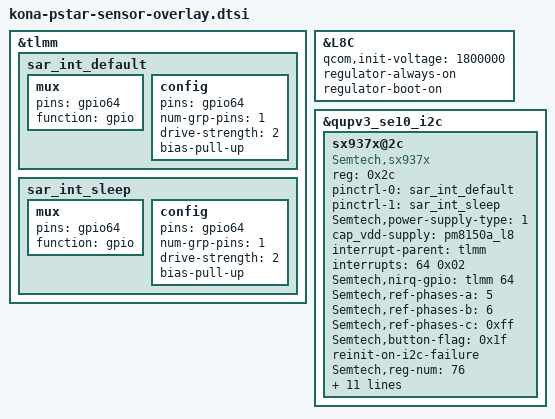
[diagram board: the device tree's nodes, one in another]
/* Copyright (c) 2019, The Linux Foundation. All rights reserved.
 *
 * This program is free software; you can redistribute it and/or modify
 * it under the terms of the GNU General Public License version 2 and
 * only version 2 as published by the Free Software Foundation.
 *
 * This program is distributed in the hope that it will be useful,
 * but WITHOUT ANY WARRANTY; without even the implied warranty of
 * MERCHANTABILITY or FITNESS FOR A PARTICULAR PURPOSE.  See the
 * GNU General Public License for more details.
 */

&tlmm {
	sar_int_default: sar_int_default {
			mux {
				pins = "gpio64";
				function =  "gpio";
			};
			config {
				pins = "gpio64";
				num-grp-pins = <1>;
				drive-strength = <2>;
				bias-pull-up;
			};
	};

	sar_int_sleep: sar_int_sleep {
			mux {
				pins = "gpio64";
				function =  "gpio";
			};
			config {
				pins = "gpio64";
				num-grp-pins = <1>;
				drive-strength = <2>;
				bias-pull-up;
			};
	};
};

&L8C {
	qcom,init-voltage = <1800000>;
	regulator-always-on;
	regulator-boot-on;
	status = "ok";
};

&qupv3_se10_i2c {
	status = "ok";
	sx937x@2c { /* SAR sensor */
		compatible = "Semtech,sx937x";
		reg = <0x2c>;
		pinctrl-names = "default","sleep";
		pinctrl-0 = <&sar_int_default>;
		pinctrl-1 = <&sar_int_sleep>;
		Semtech,power-supply-type = <1>;
		cap_vdd-supply = <&pm8150a_l8>;
		interrupt-parent = <&tlmm>;
		interrupts = <64 0x02>;
		interrupt-names = "sx937x_irq";
		Semtech,nirq-gpio= <&tlmm 64 0x02>;
		/*use PH4/5/6 as the reference sensor
		set it to 0xff if the ref-phases-x is not used*/
		Semtech,ref-phases-a = <5>;
		Semtech,ref-phases-b = <6>;
		Semtech,ref-phases-c = <0xff>;
		Semtech,button-flag = <0x1f>;
		reinit-on-i2c-failure;
		Semtech,reg-num = <76>;
		Semtech,reg-init = <
			0x8024  0x7F00 		/*PHEN, Disable all Phases*/
			0x4004  0x74 		/*irq mask*/
			0x4008  0x8
			0x8008  0x7F000081
			0x4280  0x0
			0x8020  0x32
			0x8028  0xE76 		/*AFE_PARAM_PH0*/
			0x8034  0xA76 		/*AFE_PARAM_PH1*/
			0x8040  0xE76 		/*AFE_PARAM_PH2*/
			0x804C  0x876    	/*AFE_PARAM_PH3*/
			0x8058  0xE76 		/*AFE_PARAM_PH4*/
			0x8064  0x876 		/*AFE_PARAM_PH5*/
			0x8070  0x876 		/*AFE_PARAM_PH6*/
			0x807C  0x876  		/*AFE_PARAM_PH7*/
			/*set CS3 to hiz, because it used as IRQ pin*/
			0x8030  0xBFF9FF 	/*REG_AFEPH_PH0, CS7, ANT1, Bottom center*/
			0x803C  0xFFD9FF 	/*REG_AFEPH_PH1, CS4, ANT2, Top Left*/
			0x8048  0xFFF9EF 	/*REG_AFEPH_PH2, CS5, ANT8, Bottom Right*/
			0x8054  0xFFF9FD	/*REG_AFEPH_PH3, CS1, ANT4, Right*/
			0x8060  0xFEF9FF 	/*REG_AFEPH_PH4, CS0, ANT5, Back center*/
			0x806C  0xF7F9FF 	/*REG_AFEPH_PH5, CS6, ANT1/8_REF, Bottom_Ref*/
			0x8078  0xFFF97F 	/*REG_AFEPH_PH6, CS2, ANT4/5_REF, Middle*/
			0x8084  0xFFF9FF 	/*REG_AFEPH_PH7, NOT USE*/
			0x802C  0x0
			0x8038  0xF3C3CF
			0x8044  0x940250
			0x8050  0x9BC26F
			0x805C  0x990264
			0x8068  0xD4C353
			0x8074  0xB4C2D3
			0x8080  0x0
			0x8098  0x8535
			0x80B8  0x9833
			0x80D8  0x4949
			0x80F8  0x4747
			0x8118  0x6262
			0x8138  0x7628
			0x8158  0x7628
			0x8178  0x0
			0x80A0  0x13130001
			0x80C0  0x17170002
			0x80E0  0x11110002
			0x8100  0x13130002
			0x8120  0x1A1A0002
			0x8140  0x0
			0x8160  0x0
			0x8180  0x0
			0x8188  0x8000015
			0x818C  0x8000016
			0x8190  0x0
			0x8194  0x0
			0x8090  0x46D89000
			0x80B0  0x46D59000
			0x80D0  0x3CDE9000
			0x80F0  0x64C29000
			0x8110  0x3CDE9000
			0x8130  0x2AD67000
			0x8150  0x2AD67000
			0x8170  0x0
			0x8088  0x300002
			0x80A8  0x300002
			0x80C8  0x300002
			0x80E8  0x300002
			0x8108  0x300002
			0x8128  0x500000
			0x8148  0x500000
			0x8168  0x0
			0x808C  0xE060000C
			0x80AC  0xE060000C
			0x80CC  0xE060000C
			0x80EC  0xE060000C
			0x810C  0xE060000C
			0x812C  0xE060000C
			0x814C  0xE060000C
			0x816C  0x0
			0x8024  0x7F7F
			0x4280  0xF
		>;
		/* multi parameters for the different panels,
		"support-panel-names" is the key name of the panel name from the cmdline
		the nums of "Semtech,reg-*" should be same as "Semtech,reg-init" */
		support-panel-num = <2>;
		support-panel-names = "mot_csot_nt37701_667_1080x2400_dsc_cmd","mot_visionox_nt37701_667_1080x2400_dsc_cmd";
		reg-groups-names = "Semtech,reg-0","Semtech,reg-1";
		Semtech,reg-0 = <
			0x8024  0x7F00 		/*PHEN, Disable all Phases*/
			0x4004  0x74 		/*irq mask*/
			0x4008  0x8
			0x8008  0x7F000081
			0x4280  0x0
			0x8020  0x32
			0x8028  0xE76 		/*AFE_PARAM_PH0*/
			0x8034  0xA76 		/*AFE_PARAM_PH1*/
			0x8040  0xE76 		/*AFE_PARAM_PH2*/
			0x804C  0x876    	/*AFE_PARAM_PH3*/
			0x8058  0xE76 		/*AFE_PARAM_PH4*/
			0x8064  0x876 		/*AFE_PARAM_PH5*/
			0x8070  0x876 		/*AFE_PARAM_PH6*/
			0x807C  0x876  		/*AFE_PARAM_PH7*/
			/*set CS3 to hiz, because it used as IRQ pin*/
			0x8030  0xBFF9FF 	/*REG_AFEPH_PH0, CS7, ANT1, Bottom center*/
			0x803C  0xFFD9FF 	/*REG_AFEPH_PH1, CS4, ANT2, Top Left*/
			0x8048  0xFFF9EF 	/*REG_AFEPH_PH2, CS5, ANT8, Bottom Right*/
			0x8054  0xFFF9FD	/*REG_AFEPH_PH3, CS1, ANT4, Right*/
			0x8060  0xFEF9FF 	/*REG_AFEPH_PH4, CS0, ANT5, Back center*/
			0x806C  0xF7F9FF 	/*REG_AFEPH_PH5, CS6, ANT1/8_REF, Bottom_Ref*/
			0x8078  0xFFF97F 	/*REG_AFEPH_PH6, CS2, ANT4/5_REF, Middle*/
			0x8084  0xFFF9FF 	/*REG_AFEPH_PH7, NOT USE*/
			0x802C  0x954255
			0x8038  0xF543D5
			0x8044  0x9D0274
			0x8050  0x98C263
			0x805C  0x9AC26B
			0x8068  0xD3C34F
			0x8074  0xB5C2D7
			0x8080  0x0
			0x8098  0x8535
			0x80B8  0x9833
			0x80D8  0x4949
			0x80F8  0x4747
			0x8118  0x6262
			0x8138  0x7628
			0x8158  0x7628
			0x8178  0x0
			0x80A0  0x13130001
			0x80C0  0x12120002
			0x80E0  0xC0C0002
			0x8100  0x5050002
			0x8120  0xF0F0002
			0x8140  0x0
			0x8160  0x0
			0x8180  0x0
			0x8188  0x8000015
			0x818C  0x8000016
			0x8190  0x0
			0x8194  0x0
			0x8090  0x28DF5000
			0x80B0  0x28DE5000
			0x80D0  0x28E25000
			0x80F0  0x50C45000
			0x8110  0x28E25000
			0x8130  0x15EB9000
			0x8150  0x15EB9000
			0x8170  0x0
			0x8088  0x300002
			0x80A8  0x300002
			0x80C8  0x300002
			0x80E8  0x300002
			0x8108  0x300002
			0x8128  0x500000
			0x8148  0x500000
			0x8168  0x0
			0x808C  0xE0600030
			0x80AC  0xE0600030
			0x80CC  0xE0600030
			0x80EC  0xE0600030
			0x810C  0xE0600030
			0x812C  0xE060000C
			0x814C  0xE060000C
			0x816C  0x0
			0x8024  0x7F7F
			0x4280  0xF
		>;
		Semtech,reg-1 = <
			0x8024  0x7F00 		/*PHEN, Disable all Phases*/
			0x4004  0x74 		/*irq mask*/
			0x4008  0x8
			0x8008  0x7F000081
			0x4280  0x0
			0x8020  0x32
			0x8028  0xE5E 		/*AFE_PARAM_PH0*/
			0x8034  0xA5E 		/*AFE_PARAM_PH1*/
			0x8040  0xE5E 		/*AFE_PARAM_PH2*/
			0x804C  0x85E    	/*AFE_PARAM_PH3*/
			0x8058  0xE5E 		/*AFE_PARAM_PH4*/
			0x8064  0x85E 		/*AFE_PARAM_PH5*/
			0x8070  0x85E 		/*AFE_PARAM_PH6*/
			0x807C  0x876  		/*AFE_PARAM_PH7*/
			/*set CS3 to hiz, because it used as IRQ pin*/
			0x8030  0xBFF9FF 	/*REG_AFEPH_PH0, CS7, ANT1, Bottom center*/
			0x803C  0xFFD9FF 	/*REG_AFEPH_PH1, CS4, ANT2, Top Left*/
			0x8048  0xFFF9EF 	/*REG_AFEPH_PH2, CS5, ANT8, Bottom Right*/
			0x8054  0xFFF9FD	/*REG_AFEPH_PH3, CS1, ANT4, Right*/
			0x8060  0xFEF9FF 	/*REG_AFEPH_PH4, CS0, ANT5, Back center*/
			0x806C  0xF7F9FF 	/*REG_AFEPH_PH5, CS6, ANT1/8_REF, Bottom_Ref*/
			0x8078  0xFFF97F 	/*REG_AFEPH_PH6, CS2, ANT4/5_REF, Middle*/
			0x8084  0xFFF9FF 	/*REG_AFEPH_PH7, NOT USE*/
			0x802C  0x954255
			0x8038  0xF543D5
			0x8044  0x9D0274
			0x8050  0x98C263
			0x805C  0x9AC26B
			0x8068  0xD3C34F
			0x8074  0xB5C2D7
			0x8080  0x0
			0x8098  0x8535
			0x80B8  0x9833
			0x80D8  0x4949
			0x80F8  0x4747
			0x8118  0x6262
			0x8138  0xC8
			0x8158  0xC8
			0x8178  0x0
			0x80A0  0x13130001
			0x80C0  0x12120002
			0x80E0  0xC0C0002
			0x8100  0x5050002
			0x8120  0xF0F0002
			0x8140  0x0
			0x8160  0x0
			0x8180  0x0
			0x8188  0x8000015
			0x818C  0x8000016
			0x8190  0x0
			0x8194  0x0
			0x8090  0x28DF5000
			0x80B0  0x28DF5000
			0x80D0  0x28E05000
			0x80F0  0x50C05000
			0x8110  0x28E05000
			0x8130  0xAF69000
			0x8150  0xAF69000
			0x8170  0x0
			0x8088  0x300002
			0x80A8  0x300002
			0x80C8  0x300002
			0x80E8  0x300002
			0x8108  0x300002
			0x8128  0x600000
			0x8148  0x600000
			0x8168  0x0
			0x808C  0xE0600030
			0x80AC  0xE0600030
			0x80CC  0xE0600030
			0x80EC  0xE0600030
			0x810C  0xE0600030
			0x812C  0xE060000C
			0x814C  0xE060000C
			0x816C  0x0
			0x8024  0x7F7F
			0x4280  0xF
		>;
		status = "ok";
	};
};
